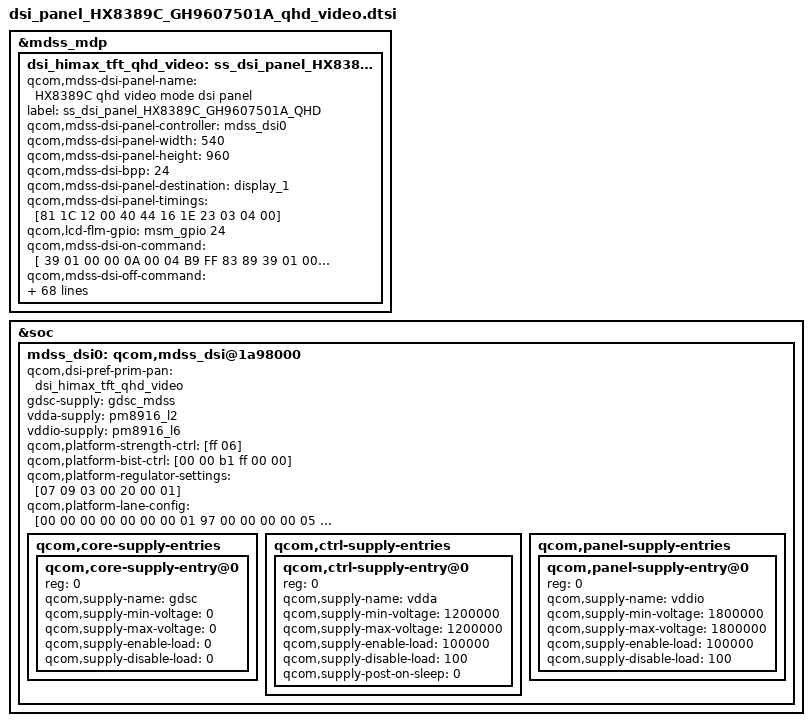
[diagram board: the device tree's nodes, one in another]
/* Copyright (c) 2013-14, Samsung Electronics Corporation. All rights reserved.
 *
 * This program is free software; you can redistribute it and/or modify
 * it under the terms of the GNU General Public License version 2 and
 * only version 2 as published by the Free Software Foundation.
 *
 * This program is distributed in the hope that it will be useful,
 * but WITHOUT ANY WARRANTY; without even the implied warranty of
 * MERCHANTABILITY or FITNESS FOR A PARTICULAR PURPOSE.  See the
 * GNU General Public License for more details.
 */

/*---------------------------------------------------------------------------
 * This file is autogenerated file using gcdb parser. Please do not edit it.
 * Update input XML file to add a new entry or update variable in this file
 * VERSION = "1.0"
 *---------------------------------------------------------------------------

 */
&mdss_mdp {
	dsi_himax_tft_qhd_video: ss_dsi_panel_HX8389C_GH9607501A_QHD {
		qcom,mdss-dsi-panel-name = "HX8389C qhd video mode dsi panel";
		label = "ss_dsi_panel_HX8389C_GH9607501A_QHD";
		qcom,mdss-dsi-panel-controller = <&mdss_dsi0>;
		qcom,mdss-dsi-panel-width = <540>;
		qcom,mdss-dsi-panel-height = <960>;
		qcom,mdss-dsi-bpp = <24>;
		qcom,mdss-dsi-panel-destination = "display_1";
		qcom,mdss-dsi-panel-timings = [81 1C 12 00 40 44 16 1E 23 03 04 00];
		qcom,lcd-flm-gpio = <&msm_gpio 24 0>;
		qcom,mdss-dsi-on-command = [
				39 01 00 00 0A 00 04 B9 FF 83 89
				39 01 00 00 00 00 15 B1 7F 10 10 D2 32 80 10 F0 56 80 20 20 F8 AA AA A1 00 80 30 00
				39 01 00 00 00 00 0B B2 82 50 05 07 F0 38 11 64 5D 09
				39 01 00 00 00 00 0C B4 66 66 66 70 00 00 18 76 28 76 A8
				39 01 00 00 00 00 02 D2 33
				39 01 00 00 00 00 05 C0 30 17 00 03
				39 01 00 00 00 00 05 C7 00 80 00 C0
				39 01 00 00 0A 00 05 BF 05 50 00 3E
				39 01 00 00 00 00 04 B9 FF 83 89
				39 01 00 00 00 00 02 CC 0E
				39 01 00 00 00 00 24 D3 00 00 00 00 00 08 00 32 10 00 00 00 03 C6 03 C6 00 00 00 00 35 33 04 04 37 00 00 00 05 08 00 00 0A 00 01
				39 01 00 00 00 00 27 D5 18 18 18 18 19 19 18 18 20 21 24 25 18 18 18 18 00 01 04 05 02 03 06 07 18 18 18 18 18 18 18 18 18 18 18 18 18 18
				39 01 00 00 00 00 27 D6 18 18 18 18 18 18 19 19 25 24 21 20 18 18 18 18 07 06 03 02 05 04 01 00 18 18 18 18 18 18 18 18 18 18 18 18 18 18
				39 01 00 00 00 00 04 B7 20 80 00
				39 01 00 00 00 00 2B E0 00 02 06 38 3C 3F 1B 46 06 09 0C 17 10 13 16 13 14 08 13 15 19 00 02 06 37 3C 3F 1A 45 05 09 0B 16 0F 13 15 13 14 07 12 14 18
				39 01 00 00 00 00 02 BD 00
				39 01 00 00 00 00 2C C1 00 00 08 10 18 20 28 30 38 40 48 50 58 60 68 70 78 80 88 90 98 A0 A8 B0 B8 C0 C8 D0 D8 E0 E8 F0 F8 FF 00 00 00 00 00 00 00 00 00
				39 01 00 00 00 00 02 BD 01
				39 01 00 00 00 00 2B C1 00 08 10 18 20 28 30 38 40 48 50 58 60 68 70 78 80 88 90 98 A0 A8 B0 B8 C0 C8 D0 D8 E0 E8 F0 F8 FF 00 00 00 00 00 00 00 00 00
				39 01 00 00 00 00 02 BD 02
				39 01 00 00 00 00 2B C1 00 08 10 18 20 28 30 38 40 48 50 58 60 68 70 78 80 88 90 98 A0 A8 B0 B8 C0 C8 D0 D8 E0 E8 F0 F8 FF 00 00 00 00 00 00 00 00 00
				/*CABC Begin*/
				39 01 00 00 05 00 0E C9 1F 00 0F 1E 81 1E 00 00 01 19 00 00 20  /* CABC PWM output to 25Khz*/
				39 01 00 00 05 00 02 55 00			/*Turn off CABC*/
				39 01 00 00 05 00 02 53 24 /*Enable Backlight Control */
				/* CABC end*/
				05 01 00 00 7D 00 02 11 00
				05 01 00 00 05 00 02 29 00
					];
		qcom,mdss-dsi-off-command = [
						/* < Deep Sleep In Sequence > */
						39 01 00 00 3C 00 02 28 00
						39 01 00 00 3C 00 02 10 00
					];
		qcom,mdss-dsi-panel-type = "dsi_video_mode";
		qcom,lcd-esd-det-gpio = <&msm_gpio 69 0>;
		qcom,mdss-dsi-panel-framerate = <60>;
		qcom,mdss-dsi-virtual-channel-id = <0>;
		qcom,mdss-dsi-stream = <0>;
		qcom,cont-splash-enabled;

		qcom,mdss-dsi-h-front-porch = <10>;
		qcom,mdss-dsi-h-back-porch = <10>;
		qcom,mdss-dsi-h-pulse-width = <14>;
		qcom,mdss-dsi-h-sync-skew = <0>;
		qcom,mdss-dsi-v-back-porch = <5>;
		qcom,mdss-dsi-v-front-porch = <9>;
		qcom,mdss-dsi-v-pulse-width = <2>;
		qcom,mdss-dsi-h-left-border = <0>;
		qcom,mdss-dsi-h-right-border = <0>;
		qcom,mdss-dsi-v-top-border = <0>;
		qcom,mdss-dsi-v-bottom-border = <0>;
		qcom,mdss-dsi-color-order = <0>;
		qcom,mdss-dsi-underflow-color = <0xff>;
		qcom,mdss-dsi-border-color = <0>;
		/* Overridden in board device tree as this functionality changes between hardware revision */
		qcom,mdss-dsi-lane-0-state;
		qcom,mdss-dsi-on-command-state = "dsi_lp_mode";
		qcom,mdss-dsi-off-command-state = "dsi_hs_mode";
		qcom,mdss-dsi-lane-1-state;
		qcom,mdss-dsi-h-sync-pulse = <0>;
		qcom,mdss-dsi-traffic-mode = "non_burst_sync_pulse";
		qcom,mdss-dsi-bllp-eof-power-mode;
		qcom,mdss-dsi-bllp-power-mode;
		qcom,mdss-dsi-lane-map = <0>;
		qcom,mdss-dsi-t-clk-post = <0x04>;
		qcom,mdss-dsi-t-clk-pre = <0x18>;
		qcom,mdss-dsi-bl-min-level = <1>;
		qcom,mdss-dsi-bl-max-level = <255>;
		qcom,mdss-dsi-dma-trigger = "trigger_sw";
		qcom,mdss-dsi-mdp-trigger = "none";
		qcom,mdss-dsi-bl-pmic-control-type = "bl_ctrl_dcs";
		qcom,mdss-dsi-reset-sequence = <1 10>, <0 2>, <1 80>;
		qcom,mdss-pan-physical-width-dimension = <62>; /* <Width> real size of panel in mm */
		qcom,mdss-pan-physical-height-dimension = <110>; /*<Height> real size of panel in mm */
		qcom,mdss-dsi-lp11-init;
		qcom,mdss-force-clk-lane-hs;
		qcom,mdss-dsi-init-delay-us = <100>;
		qcom,mdss-power-off-delay-us = <200>;
		samsung,mdss-dsi-off-reset-delay-us = <200>;
		samsung,mdss-power-on-reset-delay-us = <100>;
/*
 * ************************************************************************************************************************************
 *
 *
 *			Below  parameters are samsung dependent thigs
 *
 *
 * ************************************************************************************************************************************
 */
		samsung,tft-common-support;
		samsung,panel-vendor = "INH";
		samsung,packet_size_tx_cmds_revA = [
			37 01 00 00 00 00 02 07 00
		];
		/*
		 * First parameters can be changed
		 * by function of samsung_nv_read()
		 * because of that means offset of
		 * read position
		 */
		samsung,reg_read_pos_tx_cmds_revA = [
			15 01 00 00 00 00 02 B0 00
		];
		samsung,manufacture_id0_rx_cmds_revA = [06 01 00 00 00 00 01 da 03 00];
		samsung,manufacture_id1_rx_cmds_revA = [06 01 00 00 00 00 01 db 03 00];
		samsung,manufacture_id2_rx_cmds_revA = [06 01 00 00 00 00 01 dc 03 00];
		/*
		 * Command sets for CABC control
		 */
		samsung,tft_pwm_tx_cmds_revA=[
			39 01 00 00 00 00 02 51 FF/*First command should be PWM duty change command*/
		];
		samsung,cabc_on_tx_cmds_revA = [
			39 01 00 00 00 00 02 55 01
		];
		samsung,cabc_off_tx_cmds_revA = [
			39 01 00 00 05 00 02 55 00			/*Turn off CABC*/
		];
		/*
		* ************************************************************************************************************************
		* Scaled level to index mappings
		* ************************************************************************************************************************
		*/
		samsung,scaled_level_map_table_revA = <
		/* <idx>	    <from>       <till>     <scaled_level> */
			0		0		0		0
			1		1		7		14
			2		8		9		15
			3		10		12		16
			4		13		14		17
			5		15		17		18
			6		18		19		19
			7		20		22		20
			8		23		24		21
			9		25		27		22
			10		28		29		24
			11		30		32		26
			12		33		34		28
			13		35		37		30
			14		38		39		32
			15		40		42		34
			16		43		44		36
			17		45		47		38
			18		48		49		40
			19		50		52		42
			20		53		54		44
			21		55		57		46
			22		58		59		48
			23		60		62		50
			24		63		64		52
			25		65		67		54
			26		68		70		56
			27		71		72		58
			28		73		75		60
			29		76		77		62
			30		78		80		64
			31		81		82		66
			32		83		85		68
			33		86		87		70
			34		88		90		72
			35		91		92		74
			36		93		95		76
			37		96		97		78
			38		98		100		79
			39		101		102		80
			40		103		105		81
			41		106		107		82
			42		108		110		83
			43		111		112		84
			44		113		115		85
			45		116		117		86
			46		118		120		87
			47		121		122		89
			48		123		125		90
			49		126		127		91
			50		128		130		92
			51		131		133		96
			52		134		135		100
			53		136		138		104
			54		139		140		110
			55		141		143		114
			56		144		145		116
			57		146		148		118
			58		149		150		121
			59		151		153		123
			60		154		155		126
			61		156		158		129
			62		159		160		132
			63		161		163		135
			64		164		165		138
			65		166		168		141
			66		169		170		144
			67		171		173		147
			68		174		175		150
			69		176		178		153
			70		179		180		156
			71		181		183		159
			72		184		185		162
			73		186		188		165
			74		189		190		168
			75		191		193		171
			76		194		196		174
			77		197		198		177
			78		199		201		180
			79		202		203		183
			80		204		206		186
			81		207		208		189
			82		209		211		192
			83		212		213		195
			84		214		216		198
			85		217		218		201
			86		219		221		204
			87		222		223		207
			88		224		226		210
			89		227		228		213
			90		229		231		216
			91		232		233		219
			92		234		236		222
			93		237		238		225
			94		239		241		228
			95		242		243		231
			96		244		246		234
			97		247		248		237
			98		249		251		240
			99		252		253		243
			100		254		255		246
		>;

	};
};
&soc {
	mdss_dsi0: qcom,mdss_dsi@1a98000 {
		qcom,dsi-pref-prim-pan = <&dsi_himax_tft_qhd_video>;
		gdsc-supply = <&gdsc_mdss>;
		vdda-supply = <&pm8916_l2>;
		vddio-supply = <&pm8916_l6>;
		qcom,platform-strength-ctrl = [ff 06];
		qcom,platform-bist-ctrl = [00 00 b1 ff 00 00];
		qcom,platform-regulator-settings = [07 09 03 00 20 00 01];
		qcom,platform-lane-config = [00 00 00 00 00 00 00 01 97
			00 00 00 00 05 00 00 01 97
			00 00 00 00 0a 00 00 01 97
			00 00 00 00 0f 00 00 01 97
			00 c0 00 00 00 00 00 01 bb];
		qcom,core-supply-entries {
			#address-cells = <1>;
			#size-cells = <0>;

			qcom,core-supply-entry@0 {
				reg = <0>;
				qcom,supply-name = "gdsc";
				qcom,supply-min-voltage = <0>;
				qcom,supply-max-voltage = <0>;
				qcom,supply-enable-load = <0>;
				qcom,supply-disable-load = <0>;
			};
		};
		qcom,ctrl-supply-entries {
			#address-cells = <1>;
			#size-cells = <0>;

			qcom,ctrl-supply-entry@0 {
				reg = <0>;
				qcom,supply-name = "vdda";
				qcom,supply-min-voltage = <1200000>;
				qcom,supply-max-voltage = <1200000>;
				qcom,supply-enable-load = <100000>;
				qcom,supply-disable-load = <100>;
				qcom,supply-post-on-sleep = <0>;
			};
		};
		qcom,panel-supply-entries {
			#address-cells = <1>;
			#size-cells = <0>;

			qcom,panel-supply-entry@0 {
				reg = <0>;
				qcom,supply-name = "vddio";
				qcom,supply-min-voltage = <1800000>;
				qcom,supply-max-voltage = <1800000>;
				qcom,supply-enable-load = <100000>;
				qcom,supply-disable-load = <100>;
			};
		};
	};
};

